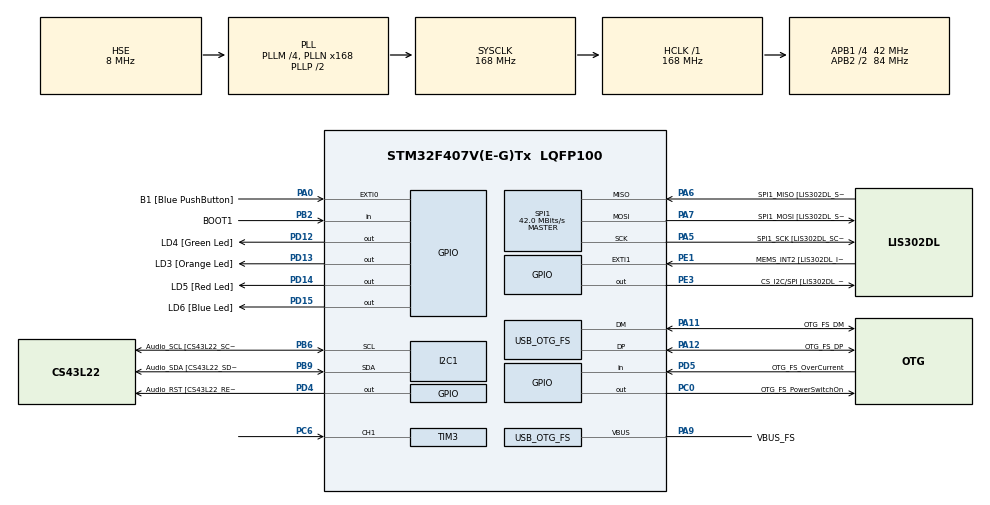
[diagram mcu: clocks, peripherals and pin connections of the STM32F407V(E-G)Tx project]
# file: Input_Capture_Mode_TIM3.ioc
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Dma.Request0=TIM3_CH1/TRIG
Dma.TIM3_CH1/TRIG.0.Direction=DMA_PERIPH_TO_MEMORY
Dma.TIM3_CH1/TRIG.0.FIFOMode=DMA_FIFOMODE_DISABLE
Dma.TIM3_CH1/TRIG.0.Instance=DMA1_Stream4
Dma.TIM3_CH1/TRIG.0.MemDataAlignment=DMA_MDATAALIGN_HALFWORD
Dma.TIM3_CH1/TRIG.0.MemInc=DMA_MINC_ENABLE
Dma.TIM3_CH1/TRIG.0.Mode=DMA_CIRCULAR
Dma.TIM3_CH1/TRIG.0.PeriphDataAlignment=DMA_PDATAALIGN_HALFWORD
Dma.TIM3_CH1/TRIG.0.PeriphInc=DMA_PINC_DISABLE
Dma.TIM3_CH1/TRIG.0.Priority=DMA_PRIORITY_LOW
Mcu.Family=STM32F4
Mcu.Name=STM32F407V(E-G)Tx
Mcu.Package=LQFP100
NVIC.DMA1_Stream4_IRQn=true\:0\:0\:false\:false\:true\:false\:true\:true
NVIC.OTG_FS_IRQn=true\:0\:0\:false\:false\:true\:true\:true\:true
NVIC.PriorityGroup=NVIC_PRIORITYGROUP_0
PA0-WKUP.GPIO_Label=B1 [Blue PushButton]
PA0-WKUP.GPIO_ModeDefaultEXTI=GPIO_MODE_EVT_RISING
PA0-WKUP.GPIO_PuPd=GPIO_NOPULL
PA0-WKUP.Signal=GPXTI0
PA10.GPIO_Label=OTG_FS_ID
PA10.GPIO_Mode=GPIO_MODE_AF_PP
PA10.GPIO_PuPd=GPIO_NOPULL
PA10.GPIO_Speed=GPIO_SPEED_FREQ_LOW
PA10.Signal=USB_OTG_FS_ID
PA11.GPIO_Label=OTG_FS_DM
PA11.GPIO_Mode=GPIO_MODE_AF_PP
PA11.GPIO_PuPd=GPIO_NOPULL
PA11.GPIO_Speed=GPIO_SPEED_FREQ_LOW
PA11.Mode=Host_Only
PA11.Signal=USB_OTG_FS_DM
PA12.GPIO_Label=OTG_FS_DP
PA12.GPIO_Mode=GPIO_MODE_AF_PP
PA12.GPIO_PuPd=GPIO_NOPULL
PA12.GPIO_Speed=GPIO_SPEED_FREQ_LOW
PA12.Mode=Host_Only
PA12.Signal=USB_OTG_FS_DP
PA13.GPIO_Label=SWDIO
PA13.Mode=Serial_Wire
PA13.Signal=SYS_JTMS-SWDIO
PA14.GPIO_Label=SWCLK
PA14.Mode=Serial_Wire
PA14.Signal=SYS_JTCK-SWCLK
PA4.GPIO_Label=I2S3_WS [CS43L22_LRCK]
PA4.GPIO_Mode=GPIO_MODE_AF_PP
PA4.GPIO_PuPd=GPIO_NOPULL
PA4.GPIO_Speed=GPIO_SPEED_FREQ_LOW
PA4.Signal=I2S3_WS
PA5.GPIO_Label=SPI1_SCK [LIS302DL_SCL/SPC]
PA5.GPIO_Mode=GPIO_MODE_AF_PP
PA5.GPIO_PuPd=GPIO_NOPULL
PA5.GPIO_Speed=GPIO_SPEED_FREQ_LOW
PA5.Mode=Full_Duplex_Master
PA5.Signal=SPI1_SCK
PA6.GPIO_Label=SPI1_MISO [LIS302DL_SDO]
PA6.GPIO_Mode=GPIO_MODE_AF_PP
PA6.GPIO_PuPd=GPIO_NOPULL
PA6.GPIO_Speed=GPIO_SPEED_FREQ_LOW
PA6.Mode=Full_Duplex_Master
PA6.Signal=SPI1_MISO
PA7.GPIO_Label=SPI1_MOSI [LIS302DL_SDA/SDI/SDO]
PA7.GPIO_Mode=GPIO_MODE_AF_PP
PA7.GPIO_PuPd=GPIO_NOPULL
PA7.GPIO_Speed=GPIO_SPEED_FREQ_LOW
PA7.Mode=Full_Duplex_Master
PA7.Signal=SPI1_MOSI
PA9.GPIO_Label=VBUS_FS
PA9.GPIO_Mode=GPIO_MODE_INPUT
PA9.GPIO_PuPd=GPIO_NOPULL
PA9.Mode=Activate_VBUS
PA9.Signal=USB_OTG_FS_VBUS
PB10.GPIO_Label=CLK_IN [MP45DT02_CLK]
PB10.GPIO_Mode=GPIO_MODE_AF_PP
PB10.GPIO_PuPd=GPIO_NOPULL
PB10.GPIO_Speed=GPIO_SPEED_FREQ_LOW
PB10.Signal=I2S2_CK
PB2.GPIO_Label=BOOT1
PB2.GPIO_Mode=GPIO_MODE_INPUT
PB2.GPIO_PuPd=GPIO_NOPULL
PB2.Signal=GPIO_Input
PB3.GPIO_Label=SWO
PB3.Signal=SYS_JTDO-SWO
PB6.GPIO_Label=Audio_SCL [CS43L22_SCL]
PB6.GPIO_Mode=GPIO_MODE_AF_OD
PB6.GPIO_Pu=GPIO_PULLUP
PB6.GPIO_PuPd=GPIO_NOPULL
PB6.GPIO_Speed=GPIO_SPEED_FREQ_LOW
PB6.Mode=I2C
PB6.Signal=I2C1_SCL
PB9.GPIO_Label=Audio_SDA [CS43L22_SDA]
PB9.GPIO_Mode=GPIO_MODE_AF_OD
PB9.GPIO_Pu=GPIO_PULLUP
PB9.GPIO_PuPd=GPIO_NOPULL
PB9.GPIO_Speed=GPIO_SPEED_FREQ_LOW
PB9.Mode=I2C
PB9.Signal=I2C1_SDA
PC0.GPIO_Label=OTG_FS_PowerSwitchOn
PC0.GPIO_PuPd=GPIO_NOPULL
PC0.GPIO_Speed=GPIO_SPEED_FREQ_LOW
PC0.PinState=GPIO_PIN_SET
PC0.Signal=GPIO_Output
PC10.GPIO_Label=I2S3_SCK [CS43L22_SCLK]
PC10.GPIO_Mode=GPIO_MODE_AF_PP
PC10.GPIO_PuPd=GPIO_NOPULL
PC10.GPIO_Speed=GPIO_SPEED_FREQ_LOW
PC10.Signal=I2S3_CK
PC12.GPIO_Label=I2S3_SD [CS43L22_SDIN]
PC12.GPIO_Mode=GPIO_MODE_AF_PP
PC12.GPIO_PuPd=GPIO_NOPULL
PC12.GPIO_Speed=GPIO_SPEED_FREQ_LOW
PC12.Signal=I2S3_SD
PC14-OSC32_IN.GPIO_Label=PC14-OSC32_IN
PC14-OSC32_IN.Mode=LSE-External-Oscillator
PC14-OSC32_IN.Signal=RCC_OSC32_IN
PC15-OSC32_OUT.GPIO_Label=PC15-OSC32_OUT
PC15-OSC32_OUT.Mode=LSE-External-Oscillator
PC15-OSC32_OUT.Signal=RCC_OSC32_OUT
PC3.GPIO_Label=PDM_OUT [MP45DT02_DOUT]
PC3.GPIO_Mode=GPIO_MODE_AF_PP
PC3.GPIO_PuPd=GPIO_NOPULL
PC3.GPIO_Speed=GPIO_SPEED_FREQ_LOW
PC3.Signal=I2S2_SD
PC6.Signal=S_TIM3_CH1
PC7.GPIO_Label=I2S3_MCK [CS43L22_MCLK]
PC7.GPIO_Mode=GPIO_MODE_AF_PP
PC7.GPIO_PuPd=GPIO_NOPULL
PC7.GPIO_Speed=GPIO_SPEED_FREQ_LOW
PC7.Signal=I2S3_MCK
PD12.GPIO_Label=LD4 [Green Led]
PD12.GPIO_PuPd=GPIO_NOPULL
PD12.GPIO_Speed=GPIO_SPEED_FREQ_LOW
PD12.Signal=GPIO_Output
PD13.GPIO_Label=LD3 [Orange Led]
PD13.GPIO_PuPd=GPIO_NOPULL
PD13.GPIO_Speed=GPIO_SPEED_FREQ_LOW
PD13.Signal=GPIO_Output
PD14.GPIO_Label=LD5 [Red Led]
PD14.GPIO_PuPd=GPIO_NOPULL
PD14.GPIO_Speed=GPIO_SPEED_FREQ_LOW
PD14.Signal=GPIO_Output
PD15.GPIO_Label=LD6 [Blue Led]
PD15.GPIO_PuPd=GPIO_NOPULL
PD15.GPIO_Speed=GPIO_SPEED_FREQ_LOW
PD15.Signal=GPIO_Output
PD4.GPIO_Label=Audio_RST [CS43L22_RESET]
PD4.GPIO_PuPd=GPIO_NOPULL
PD4.GPIO_Speed=GPIO_SPEED_FREQ_LOW
PD4.Signal=GPIO_Output
PD5.GPIO_Label=OTG_FS_OverCurrent
PD5.GPIO_Mode=GPIO_MODE_INPUT
PD5.GPIO_PuPd=GPIO_NOPULL
PD5.Signal=GPIO_Input
PE1.GPIO_Label=MEMS_INT2 [LIS302DL_INT2]
PE1.GPIO_ModeDefaultEXTI=GPIO_MODE_EVT_RISING
PE1.GPIO_PuPd=GPIO_NOPULL
PE1.Signal=GPXTI1
PE3.GPIO_Label=CS_I2C/SPI [LIS302DL_CS_I2C/SPI]
PE3.GPIO_PuPd=GPIO_NOPULL
PE3.GPIO_Speed=GPIO_SPEED_FREQ_LOW
PE3.Signal=GPIO_Output
PH0-OSC_IN.GPIO_Label=PH0-OSC_IN
PH0-OSC_IN.Mode=HSE-External-Oscillator
PH0-OSC_IN.Signal=RCC_OSC_IN
PH1-OSC_OUT.GPIO_Label=PH1-OSC_OUT
PH1-OSC_OUT.Mode=HSE-External-Oscillator
PH1-OSC_OUT.Signal=RCC_OSC_OUT
ProjectManager.HeapSize=0x200
ProjectManager.StackSize=0x400
ProjectManager.TargetToolchain=STM32CubeIDE
RCC.48MHZClocksFreq_Value=48000000
RCC.AHBFreq_Value=168000000
RCC.APB1CLKDivider=RCC_HCLK_DIV4
RCC.APB1Freq_Value=42000000
RCC.APB1TimFreq_Value=84000000
RCC.APB2CLKDivider=RCC_HCLK_DIV2
RCC.APB2Freq_Value=84000000
RCC.APB2TimFreq_Value=168000000
RCC.CortexFreq_Value=168000000
RCC.HCLKFreq_Value=168000000
RCC.HSE_VALUE=8000000
RCC.HSI_VALUE=16000000
RCC.PLLI2SN=50
RCC.PLLM=4
RCC.PLLN=168
RCC.PLLQ=7
RCC.SYSCLKFreq_VALUE=168000000
RCC.SYSCLKSource=RCC_SYSCLKSOURCE_PLLCLK
RCC.VCOOutputFreq_Value=336000000
SH.S_TIM3_CH1.0=TIM3_CH1,Input_Capture1_from_TI1
SPI1.BaudRatePrescaler-Full_Duplex_Master=SPI_BAUDRATEPRESCALER_2
SPI1.CalculateBaudRate=42.0 MBits/s
SPI1.CalculateBaudRate-Full_Duplex_Master=42.0 MBits/s
SPI1.Direction=SPI_DIRECTION_2LINES
SPI1.Mode=SPI_MODE_MASTER
SPI1.Mode-Full_Duplex_Master=SPI_MODE_MASTER
SPI1.VirtualType=VM_MASTER
TIM3.Channel-Input_Capture1_from_TI1=TIM_CHANNEL_1
TIM3.ICPolarity_CH1=TIM_INPUTCHANNELPOLARITY_BOTHEDGE
TIM3.Prescaler=84 - 1
USB_HOST.BSP.number=1
USB_HOST.USBH_HandleTypeDef-CDC_FS=hUsbHostFS
USB_HOST.VirtualModeFS=Cdc
USB_HOST0.BSP.STBoard=false
USB_HOST0.BSP.api=Unknown
USB_HOST0.BSP.instance=PC0
USB_HOST0.BSP.ip=GPIO
USB_HOST0.BSP.mode=Output
USB_HOST0.BSP.name=Drive_VBUS_FS
USB_HOST0.BSP.solution=PC0
USB_OTG_FS.VirtualMode=Host_Only
USB_OTG_FS.phy_itface=HCD_PHY_EMBEDDED
VP_TIM3_VS_ClockSourceINT.Mode=Internal
VP_USB_HOST_VS_USB_HOST_CDC_FS.Mode=CDC_FS
board=STM32F407G-DISC1

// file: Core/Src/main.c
/* USER CODE BEGIN Header */
/**
  ******************************************************************************
  * @file           : main.c
  * @brief          : Main program body
  ******************************************************************************
  * @attention
  *
  * Copyright (c) 2026 STMicroelectronics.
  * All rights reserved.
  *
  * This software is licensed under terms that can be found in the LICENSE file
  * in the root directory of this software component.
  * If no LICENSE file comes with this software, it is provided AS-IS.
  *
  ******************************************************************************
  */
/* USER CODE END Header */
#include "main.h"
#include "usb_host.h"

/* USER CODE BEGIN Includes */
#include <stdint.h>
/* USER CODE END Includes */

I2C_HandleTypeDef hi2c1;

SPI_HandleTypeDef hspi1;

TIM_HandleTypeDef htim3;
DMA_HandleTypeDef hdma_tim3_ch1_trig;

/* USER CODE BEGIN PV */
// --- VARIABLES FOR INPUT CAPTURE ---
uint16_t ic_buffer[2];        // Array to store DMA captured values (Rising & Falling edge times)
uint16_t pulse_width = 0;     // The actual length of the PWM signal (e.g., 1000us to 2000us)
// --- VARIABLES FOR DRONE CONTROL ---
float target_roll_angle = 0.0f; // Calculated target angle for the drone
/* USER CODE END PV */

void SystemClock_Config(void);
static void MX_GPIO_Init(void);
static void MX_DMA_Init(void);
static void MX_I2C1_Init(void);
static void MX_SPI1_Init(void);
static void MX_TIM3_Init(void);
void MX_USB_HOST_Process(void);

int main(void)
{

  /* MCU Configuration--------------------------------------------------------*/

  /* Reset of all peripherals, Initializes the Flash interface and the Systick. */
  HAL_Init();

  /* Configure the system clock */
  SystemClock_Config();

  /* Initialize all configured peripherals */
  MX_GPIO_Init();
  MX_DMA_Init();
  MX_I2C1_Init();
  MX_SPI1_Init();
  MX_TIM3_Init();
  MX_USB_HOST_Init();
  /* USER CODE BEGIN 2 */
  // --- START SYSTEM ---
  // Start Timer 3 Channel 1 in Input Capture Mode using DMA
  // We tell it to store values in 'ic_buffer' and expect 2 values (start and end of pulse)
  HAL_TIM_IC_Start_DMA(&htim3, TIM_CHANNEL_1, (uint32_t*)ic_buffer, 2);
  /* USER CODE END 2 */

  /* Infinite loop */
  while (1)
  {
    MX_USB_HOST_Process();

  }
}

void SystemClock_Config(void)
{
  RCC_OscInitTypeDef RCC_OscInitStruct = {0};
  RCC_ClkInitTypeDef RCC_ClkInitStruct = {0};

  /** Configure the main internal regulator output voltage
  */
  __HAL_RCC_PWR_CLK_ENABLE();
  __HAL_PWR_VOLTAGESCALING_CONFIG(PWR_REGULATOR_VOLTAGE_SCALE1);

  /** Initializes the RCC Oscillators according to the specified parameters
  * in the RCC_OscInitTypeDef structure.
  */
  RCC_OscInitStruct.OscillatorType = RCC_OSCILLATORTYPE_HSE;
  RCC_OscInitStruct.HSEState = RCC_HSE_ON;
  RCC_OscInitStruct.PLL.PLLState = RCC_PLL_ON;
  RCC_OscInitStruct.PLL.PLLSource = RCC_PLLSOURCE_HSE;
  RCC_OscInitStruct.PLL.PLLM = 4;
  RCC_OscInitStruct.PLL.PLLN = 168;
  RCC_OscInitStruct.PLL.PLLP = RCC_PLLP_DIV2;
  RCC_OscInitStruct.PLL.PLLQ = 7;
  if (HAL_RCC_OscConfig(&RCC_OscInitStruct) != HAL_OK)
  {
    Error_Handler();
  }

  /** Initializes the CPU, AHB and APB buses clocks
  */
  RCC_ClkInitStruct.ClockType = RCC_CLOCKTYPE_HCLK|RCC_CLOCKTYPE_SYSCLK
                              |RCC_CLOCKTYPE_PCLK1|RCC_CLOCKTYPE_PCLK2;
  RCC_ClkInitStruct.SYSCLKSource = RCC_SYSCLKSOURCE_PLLCLK;
  RCC_ClkInitStruct.AHBCLKDivider = RCC_SYSCLK_DIV1;
  RCC_ClkInitStruct.APB1CLKDivider = RCC_HCLK_DIV4;
  RCC_ClkInitStruct.APB2CLKDivider = RCC_HCLK_DIV2;

  if (HAL_RCC_ClockConfig(&RCC_ClkInitStruct, FLASH_LATENCY_5) != HAL_OK)
  {
    Error_Handler();
  }
}

static void MX_I2C1_Init(void)
{

  hi2c1.Instance = I2C1;
  hi2c1.Init.ClockSpeed = 100000;
  hi2c1.Init.DutyCycle = I2C_DUTYCYCLE_2;
  hi2c1.Init.OwnAddress1 = 0;
  hi2c1.Init.AddressingMode = I2C_ADDRESSINGMODE_7BIT;
  hi2c1.Init.DualAddressMode = I2C_DUALADDRESS_DISABLE;
  hi2c1.Init.OwnAddress2 = 0;
  hi2c1.Init.GeneralCallMode = I2C_GENERALCALL_DISABLE;
  hi2c1.Init.NoStretchMode = I2C_NOSTRETCH_DISABLE;
  if (HAL_I2C_Init(&hi2c1) != HAL_OK)
  {
    Error_Handler();
  }

}

static void MX_SPI1_Init(void)
{

  /* SPI1 parameter configuration*/
  hspi1.Instance = SPI1;
  hspi1.Init.Mode = SPI_MODE_MASTER;
  hspi1.Init.Direction = SPI_DIRECTION_2LINES;
  hspi1.Init.DataSize = SPI_DATASIZE_8BIT;
  hspi1.Init.CLKPolarity = SPI_POLARITY_LOW;
  hspi1.Init.CLKPhase = SPI_PHASE_1EDGE;
  hspi1.Init.NSS = SPI_NSS_SOFT;
  hspi1.Init.BaudRatePrescaler = SPI_BAUDRATEPRESCALER_2;
  hspi1.Init.FirstBit = SPI_FIRSTBIT_MSB;
  hspi1.Init.TIMode = SPI_TIMODE_DISABLE;
  hspi1.Init.CRCCalculation = SPI_CRCCALCULATION_DISABLE;
  hspi1.Init.CRCPolynomial = 10;
  if (HAL_SPI_Init(&hspi1) != HAL_OK)
  {
    Error_Handler();
  }

}

static void MX_TIM3_Init(void)
{

  TIM_ClockConfigTypeDef sClockSourceConfig = {0};
  TIM_MasterConfigTypeDef sMasterConfig = {0};
  TIM_IC_InitTypeDef sConfigIC = {0};

  htim3.Instance = TIM3;
  htim3.Init.Prescaler = 84 - 1;
  htim3.Init.CounterMode = TIM_COUNTERMODE_UP;
  htim3.Init.Period = 65535;
  htim3.Init.ClockDivision = TIM_CLOCKDIVISION_DIV1;
  htim3.Init.AutoReloadPreload = TIM_AUTORELOAD_PRELOAD_DISABLE;
  if (HAL_TIM_Base_Init(&htim3) != HAL_OK)
  {
    Error_Handler();
  }
  sClockSourceConfig.ClockSource = TIM_CLOCKSOURCE_INTERNAL;
  if (HAL_TIM_ConfigClockSource(&htim3, &sClockSourceConfig) != HAL_OK)
  {
    Error_Handler();
  }
  if (HAL_TIM_IC_Init(&htim3) != HAL_OK)
  {
    Error_Handler();
  }
  sMasterConfig.MasterOutputTrigger = TIM_TRGO_RESET;
  sMasterConfig.MasterSlaveMode = TIM_MASTERSLAVEMODE_DISABLE;
  if (HAL_TIMEx_MasterConfigSynchronization(&htim3, &sMasterConfig) != HAL_OK)
  {
    Error_Handler();
  }
  sConfigIC.ICPolarity = TIM_INPUTCHANNELPOLARITY_BOTHEDGE;
  sConfigIC.ICSelection = TIM_ICSELECTION_DIRECTTI;
  sConfigIC.ICPrescaler = TIM_ICPSC_DIV1;
  sConfigIC.ICFilter = 0;
  if (HAL_TIM_IC_ConfigChannel(&htim3, &sConfigIC, TIM_CHANNEL_1) != HAL_OK)
  {
    Error_Handler();
  }

}

static void MX_DMA_Init(void)
{

  /* DMA controller clock enable */
  __HAL_RCC_DMA1_CLK_ENABLE();

  /* DMA interrupt init */
  /* DMA1_Stream4_IRQn interrupt configuration */
  HAL_NVIC_SetPriority(DMA1_Stream4_IRQn, 0, 0);
  HAL_NVIC_EnableIRQ(DMA1_Stream4_IRQn);

}

static void MX_GPIO_Init(void)
{
  GPIO_InitTypeDef GPIO_InitStruct = {0};

  /* GPIO Ports Clock Enable */
  __HAL_RCC_GPIOE_CLK_ENABLE();
  __HAL_RCC_GPIOC_CLK_ENABLE();
  __HAL_RCC_GPIOH_CLK_ENABLE();
  __HAL_RCC_GPIOA_CLK_ENABLE();
  __HAL_RCC_GPIOB_CLK_ENABLE();
  __HAL_RCC_GPIOD_CLK_ENABLE();

  /*Configure GPIO pin Output Level */
  HAL_GPIO_WritePin(CS_I2C_SPI_GPIO_Port, CS_I2C_SPI_Pin, GPIO_PIN_RESET);

  /*Configure GPIO pin Output Level */
  HAL_GPIO_WritePin(OTG_FS_PowerSwitchOn_GPIO_Port, OTG_FS_PowerSwitchOn_Pin, GPIO_PIN_SET);

  /*Configure GPIO pin Output Level */
  HAL_GPIO_WritePin(GPIOD, LD4_Pin|LD3_Pin|LD5_Pin|LD6_Pin
                          |Audio_RST_Pin, GPIO_PIN_RESET);

  /*Configure GPIO pin : CS_I2C_SPI_Pin */
  GPIO_InitStruct.Pin = CS_I2C_SPI_Pin;
  GPIO_InitStruct.Mode = GPIO_MODE_OUTPUT_PP;
  GPIO_InitStruct.Pull = GPIO_NOPULL;
  GPIO_InitStruct.Speed = GPIO_SPEED_FREQ_LOW;
  HAL_GPIO_Init(CS_I2C_SPI_GPIO_Port, &GPIO_InitStruct);

  /*Configure GPIO pin : OTG_FS_PowerSwitchOn_Pin */
  GPIO_InitStruct.Pin = OTG_FS_PowerSwitchOn_Pin;
  GPIO_InitStruct.Mode = GPIO_MODE_OUTPUT_PP;
  GPIO_InitStruct.Pull = GPIO_NOPULL;
  GPIO_InitStruct.Speed = GPIO_SPEED_FREQ_LOW;
  HAL_GPIO_Init(OTG_FS_PowerSwitchOn_GPIO_Port, &GPIO_InitStruct);

  /*Configure GPIO pin : PDM_OUT_Pin */
  GPIO_InitStruct.Pin = PDM_OUT_Pin;
  GPIO_InitStruct.Mode = GPIO_MODE_AF_PP;
  GPIO_InitStruct.Pull = GPIO_NOPULL;
  GPIO_InitStruct.Speed = GPIO_SPEED_FREQ_LOW;
  GPIO_InitStruct.Alternate = GPIO_AF5_SPI2;
  HAL_GPIO_Init(PDM_OUT_GPIO_Port, &GPIO_InitStruct);

  /*Configure GPIO pin : B1_Pin */
  GPIO_InitStruct.Pin = B1_Pin;
  GPIO_InitStruct.Mode = GPIO_MODE_EVT_RISING;
  GPIO_InitStruct.Pull = GPIO_NOPULL;
  HAL_GPIO_Init(B1_GPIO_Port, &GPIO_InitStruct);

  /*Configure GPIO pin : I2S3_WS_Pin */
  GPIO_InitStruct.Pin = I2S3_WS_Pin;
  GPIO_InitStruct.Mode = GPIO_MODE_AF_PP;
  GPIO_InitStruct.Pull = GPIO_NOPULL;
  GPIO_InitStruct.Speed = GPIO_SPEED_FREQ_LOW;
  GPIO_InitStruct.Alternate = GPIO_AF6_SPI3;
  HAL_GPIO_Init(I2S3_WS_GPIO_Port, &GPIO_InitStruct);

  /*Configure GPIO pin : BOOT1_Pin */
  GPIO_InitStruct.Pin = BOOT1_Pin;
  GPIO_InitStruct.Mode = GPIO_MODE_INPUT;
  GPIO_InitStruct.Pull = GPIO_NOPULL;
  HAL_GPIO_Init(BOOT1_GPIO_Port, &GPIO_InitStruct);

  /*Configure GPIO pin : CLK_IN_Pin */
  GPIO_InitStruct.Pin = CLK_IN_Pin;
  GPIO_InitStruct.Mode = GPIO_MODE_AF_PP;
  GPIO_InitStruct.Pull = GPIO_NOPULL;
  GPIO_InitStruct.Speed = GPIO_SPEED_FREQ_LOW;
  GPIO_InitStruct.Alternate = GPIO_AF5_SPI2;
  HAL_GPIO_Init(CLK_IN_GPIO_Port, &GPIO_InitStruct);

  /*Configure GPIO pins : LD4_Pin LD3_Pin LD5_Pin LD6_Pin
                           Audio_RST_Pin */
  GPIO_InitStruct.Pin = LD4_Pin|LD3_Pin|LD5_Pin|LD6_Pin
                          |Audio_RST_Pin;
  GPIO_InitStruct.Mode = GPIO_MODE_OUTPUT_PP;
  GPIO_InitStruct.Pull = GPIO_NOPULL;
  GPIO_InitStruct.Speed = GPIO_SPEED_FREQ_LOW;
  HAL_GPIO_Init(GPIOD, &GPIO_InitStruct);

  /*Configure GPIO pins : I2S3_MCK_Pin I2S3_SCK_Pin I2S3_SD_Pin */
  GPIO_InitStruct.Pin = I2S3_MCK_Pin|I2S3_SCK_Pin|I2S3_SD_Pin;
  GPIO_InitStruct.Mode = GPIO_MODE_AF_PP;
  GPIO_InitStruct.Pull = GPIO_NOPULL;
  GPIO_InitStruct.Speed = GPIO_SPEED_FREQ_LOW;
  GPIO_InitStruct.Alternate = GPIO_AF6_SPI3;
  HAL_GPIO_Init(GPIOC, &GPIO_InitStruct);

  /*Configure GPIO pin : OTG_FS_OverCurrent_Pin */
  GPIO_InitStruct.Pin = OTG_FS_OverCurrent_Pin;
  GPIO_InitStruct.Mode = GPIO_MODE_INPUT;
  GPIO_InitStruct.Pull = GPIO_NOPULL;
  HAL_GPIO_Init(OTG_FS_OverCurrent_GPIO_Port, &GPIO_InitStruct);

  /*Configure GPIO pin : MEMS_INT2_Pin */
  GPIO_InitStruct.Pin = MEMS_INT2_Pin;
  GPIO_InitStruct.Mode = GPIO_MODE_EVT_RISING;
  GPIO_InitStruct.Pull = GPIO_NOPULL;
  HAL_GPIO_Init(MEMS_INT2_GPIO_Port, &GPIO_InitStruct);

}

/* USER CODE BEGIN 4 */
// --- DMA INTERRUPT CALLBACK ---
// This function is automatically called by the system every time DMA fills the 'ic_buffer' (2 captures)
void HAL_TIM_IC_CaptureCallback(TIM_HandleTypeDef *htim)
{
    if (htim->Instance == TIM3 && htim->Channel == HAL_TIM_ACTIVE_CHANNEL_1)
    {
        // ---------------------------------------------------------
        // STEP 1: MATHEMATICS (CALCULATE PULSE WIDTH)
        // ---------------------------------------------------------
        // The first value ic_buffer[0] is the time when signal went HIGH (Rising Edge)
        // The second value ic_buffer[1] is the time when signal went LOW (Falling Edge)

        if (ic_buffer[1] >= ic_buffer[0])
        {
            // Normal case: Just subtract the start time from the end time
            pulse_width = ic_buffer[1] - ic_buffer[0];
        }
        else
        {
            // Overflow case: The timer reached 65535 and reset to 0 between edges
            pulse_width = (65535 - ic_buffer[0]) + ic_buffer[1] + 1;
        }

        // Now 'pulse_width' contains a value typically between 1000 and 2000 microseconds.

        // ---------------------------------------------------------
        // STEP 2: MAPPING (TRANSLATE JOYSTICK TO ANGLE)
        // ---------------------------------------------------------
        // Here you convert the raw microseconds into a physical angle for the drone.
        // Example: 1500us = 0 degrees, 1000us = -30 degrees, 2000us = +30 degrees.

        // Let's create a simple map function logic:
        // (pulse_width - 1500) gives a range from -500 to +500.
        // Multiply by an angle factor to get degrees.

        target_roll_angle = (pulse_width - 1500) * (30.0f / 500.0f);

        // Limit the angle just in case the receiver sends a noisy signal (Safety Check)
        if (target_roll_angle > 30.0f) target_roll_angle = 30.0f;
        if (target_roll_angle < -30.0f) target_roll_angle = -30.0f;

        // ---------------------------------------------------------
        // STEP 3: PID CONTROLLER TRIGGER (FUTURE STEP)
        // ---------------------------------------------------------
        // Here you will pass the 'target_roll_angle' to your PID calculation function.
        // You will also read the MPU6050 (Gyroscope) here or in a separate loop to get the CURRENT angle.
        // PID_Calculate(target_roll_angle, current_gyro_angle);

    }
}
/* USER CODE END 4 */

void Error_Handler(void)
{
  __disable_irq();
  while (1)
  {
  }
}
